# HC32K118 register map
File version: 1.0
CPU: CM0+ r0p1, little endian, no MPU, no FPU, 2 interrupt priority bits
Registers are 32-bit, read-write, reset 0x0 unless marked. A register's access mark holds for its fields unless they carry their own. Offsets are from the block's base; [hi:lo] are bit positions; {n}, {i} and the like mark numbered series; 'fields as' and 'values as' point back to an identical list.

## ICGA
Base 0x01000A00
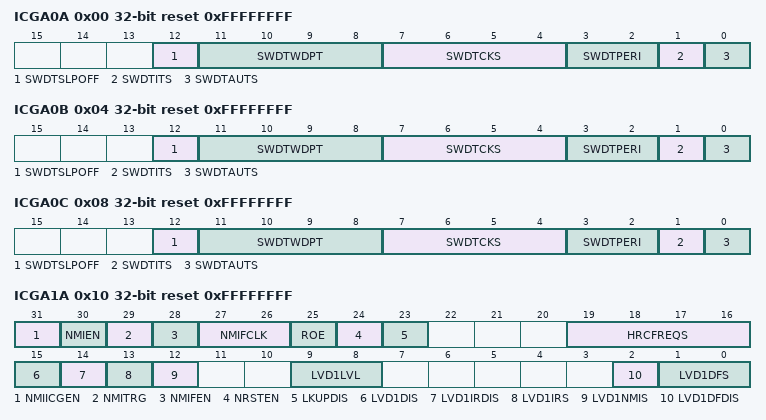
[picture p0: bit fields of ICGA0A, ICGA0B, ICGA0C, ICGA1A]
0x00 ICGA0A ro reset 0xFFFFFFFF
  [12] SWDTSLPOFF, [11:8] SWDTWDPT, [7:4] SWDTCKS, [3:2] SWDTPERI, [1] SWDTITS, [0] SWDTAUTS
0x04 ICGA0B ro reset 0xFFFFFFFF
  fields as ICGA0A
0x08 ICGA0C ro reset 0xFFFFFFFF
  fields as ICGA0A
0x10 ICGA1A ro reset 0xFFFFFFFF
  [31] NMIICGEN, [30] NMIEN, [29] NMITRG, [28] NMIFEN, [27:26] NMIFCLK, [25] ROE, [24] NRSTEN, [23] LKUPDIS, [19:16] HRCFREQS, [15] LVD1DIS, [14] LVD1IRDIS, [13] LVD1IRS, [12] LVD1NMIS, [9:8] LVD1LVL, [2] LVD1DFDIS, [1:0] LVD1DFS
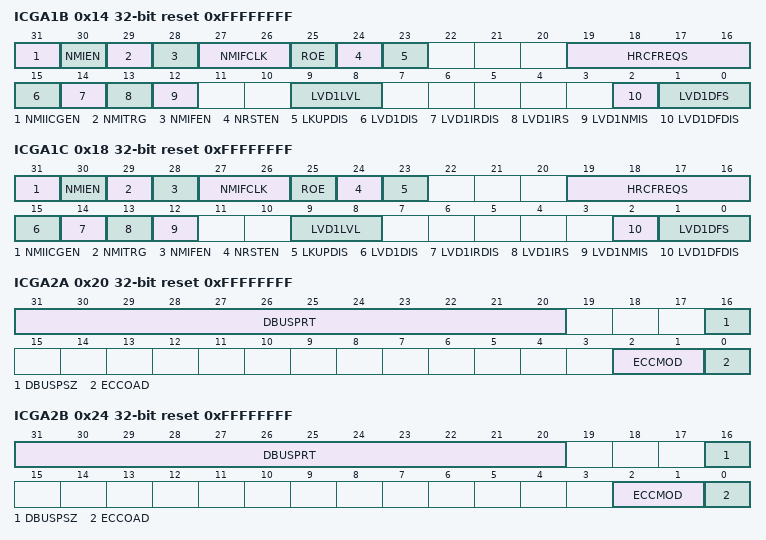
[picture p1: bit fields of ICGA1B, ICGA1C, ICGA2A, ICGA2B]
0x14 ICGA1B ro reset 0xFFFFFFFF
  fields as ICGA1A
0x18 ICGA1C ro reset 0xFFFFFFFF
  fields as ICGA1A
0x20 ICGA2A ro reset 0xFFFFFFFF
  [31:20] DBUSPRT, [16] DBUSPSZ, [2:1] ECCMOD, [0] ECCOAD
0x24 ICGA2B ro reset 0xFFFFFFFF
  [31:20] DBUSPRT, [16] DBUSPSZ, [2:1] ECCMOD, [0] ECCOAD
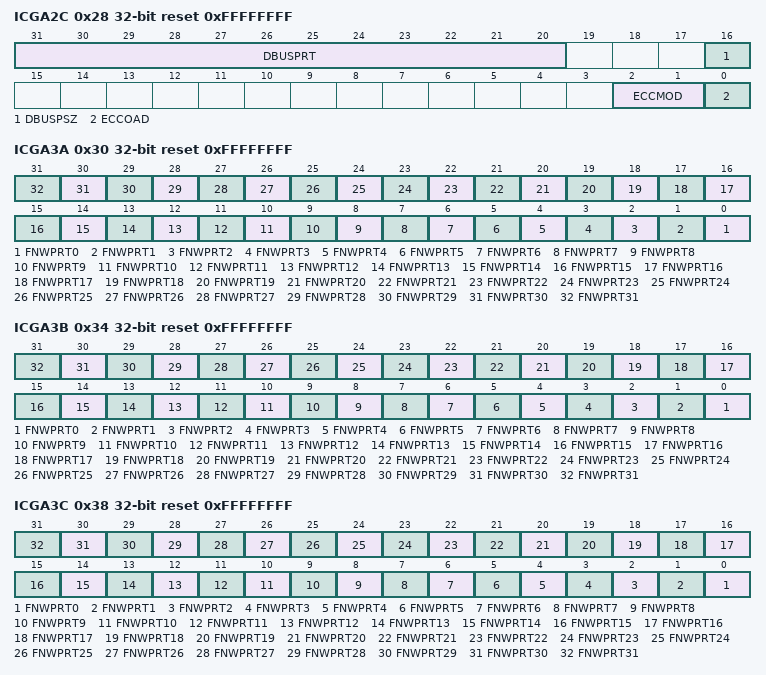
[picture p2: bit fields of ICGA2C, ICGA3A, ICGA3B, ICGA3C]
0x28 ICGA2C ro reset 0xFFFFFFFF
  [31:20] DBUSPRT, [16] DBUSPSZ, [2:1] ECCMOD, [0] ECCOAD
0x30 ICGA3A ro reset 0xFFFFFFFF
  [n] FNWPRT{n} (n=0..31)
0x34 ICGA3B ro reset 0xFFFFFFFF
  [n] FNWPRT{n} (n=0..31)
0x38 ICGA3C ro reset 0xFFFFFFFF
  [n] FNWPRT{n} (n=0..31)
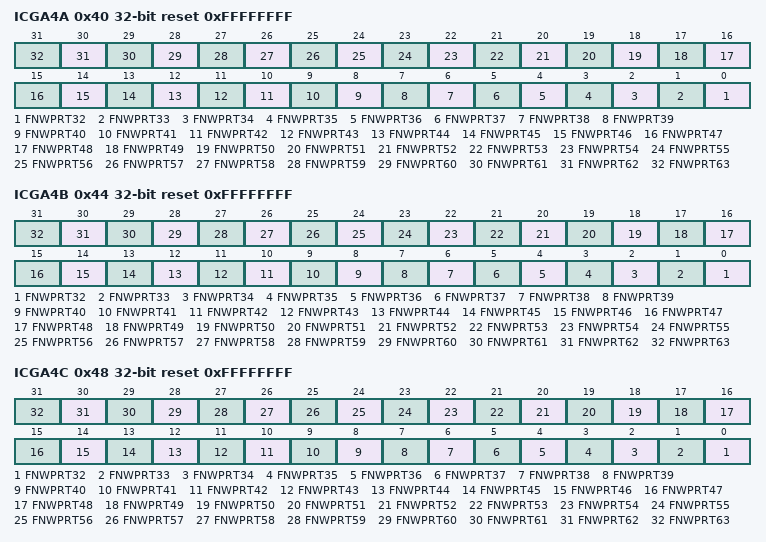
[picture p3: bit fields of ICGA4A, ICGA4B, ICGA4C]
0x40 ICGA4A ro reset 0xFFFFFFFF
  [n-32] FNWPRT{n} (n=32..63)
0x44 ICGA4B ro reset 0xFFFFFFFF
  [n-32] FNWPRT{n} (n=32..63)
0x48 ICGA4C ro reset 0xFFFFFFFF
  [n-32] FNWPRT{n} (n=32..63)

## ICGB
Base 0x40017800
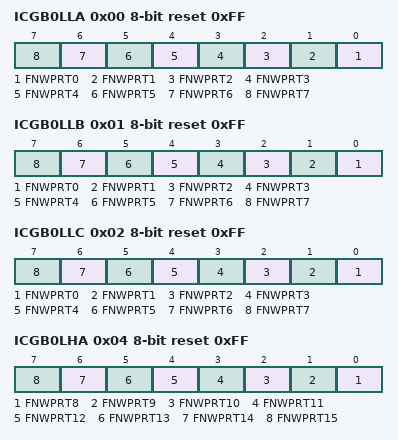
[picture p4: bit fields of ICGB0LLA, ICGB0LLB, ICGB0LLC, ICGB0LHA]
0x00 ICGB0LLA 8-bit ro reset 0xFF
  [n] FNWPRT{n} (n=0..7)
0x01 ICGB0LLB 8-bit ro reset 0xFF
  [n] FNWPRT{n} (n=0..7)
0x02 ICGB0LLC 8-bit ro reset 0xFF
  [n] FNWPRT{n} (n=0..7)
0x04 ICGB0LHA 8-bit ro reset 0xFF
  [n-8] FNWPRT{n} (n=8..15)
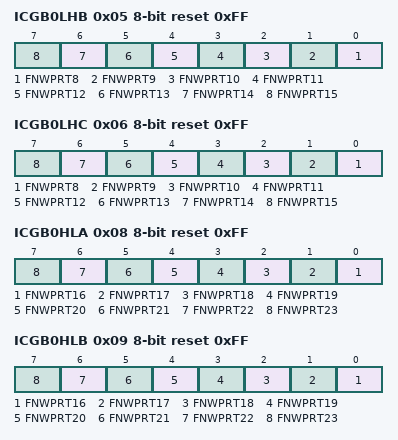
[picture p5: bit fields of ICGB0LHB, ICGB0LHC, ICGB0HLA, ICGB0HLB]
0x05 ICGB0LHB 8-bit ro reset 0xFF
  [n-8] FNWPRT{n} (n=8..15)
0x06 ICGB0LHC 8-bit ro reset 0xFF
  [n-8] FNWPRT{n} (n=8..15)
0x08 ICGB0HLA 8-bit ro reset 0xFF
  [n-16] FNWPRT{n} (n=16..23)
0x09 ICGB0HLB 8-bit ro reset 0xFF
  [n-16] FNWPRT{n} (n=16..23)
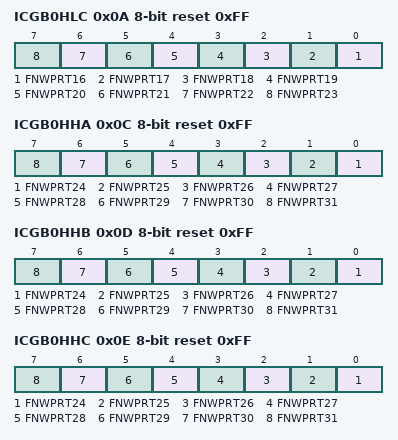
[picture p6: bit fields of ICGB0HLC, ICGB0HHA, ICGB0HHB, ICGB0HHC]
0x0A ICGB0HLC 8-bit ro reset 0xFF
  [n-16] FNWPRT{n} (n=16..23)
0x0C ICGB0HHA 8-bit ro reset 0xFF
  [n-24] FNWPRT{n} (n=24..31)
0x0D ICGB0HHB 8-bit ro reset 0xFF
  [n-24] FNWPRT{n} (n=24..31)
0x0E ICGB0HHC 8-bit ro reset 0xFF
  [n-24] FNWPRT{n} (n=24..31)
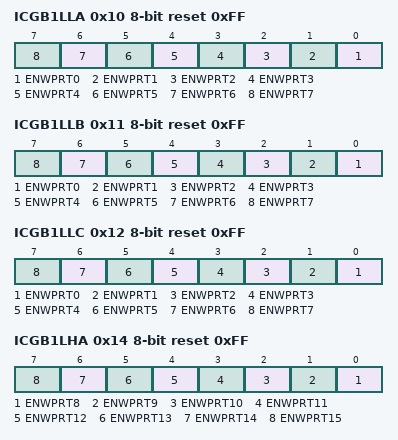
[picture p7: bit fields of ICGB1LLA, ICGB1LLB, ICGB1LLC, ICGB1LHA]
0x10 ICGB1LLA 8-bit ro reset 0xFF
  [n] ENWPRT{n} (n=0..7)
0x11 ICGB1LLB 8-bit ro reset 0xFF
  [n] ENWPRT{n} (n=0..7)
0x12 ICGB1LLC 8-bit ro reset 0xFF
  [n] ENWPRT{n} (n=0..7)
0x14 ICGB1LHA 8-bit ro reset 0xFF
  [n-8] ENWPRT{n} (n=8..15)
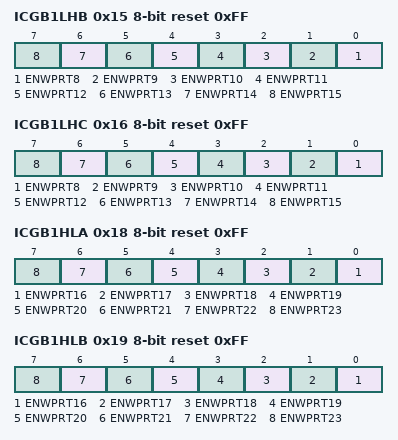
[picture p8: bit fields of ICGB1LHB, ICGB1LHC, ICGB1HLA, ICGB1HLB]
0x15 ICGB1LHB 8-bit ro reset 0xFF
  [n-8] ENWPRT{n} (n=8..15)
0x16 ICGB1LHC 8-bit ro reset 0xFF
  [n-8] ENWPRT{n} (n=8..15)
0x18 ICGB1HLA 8-bit ro reset 0xFF
  [n-16] ENWPRT{n} (n=16..23)
0x19 ICGB1HLB 8-bit ro reset 0xFF
  [n-16] ENWPRT{n} (n=16..23)
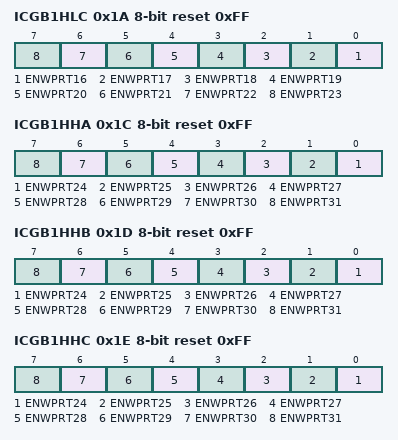
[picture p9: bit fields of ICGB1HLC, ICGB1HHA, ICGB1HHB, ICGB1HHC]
0x1A ICGB1HLC 8-bit ro reset 0xFF
  [n-16] ENWPRT{n} (n=16..23)
0x1C ICGB1HHA 8-bit ro reset 0xFF
  [n-24] ENWPRT{n} (n=24..31)
0x1D ICGB1HHB 8-bit ro reset 0xFF
  [n-24] ENWPRT{n} (n=24..31)
0x1E ICGB1HHC 8-bit ro reset 0xFF
  [n-24] ENWPRT{n} (n=24..31)

## INTC
Base 0x40011000
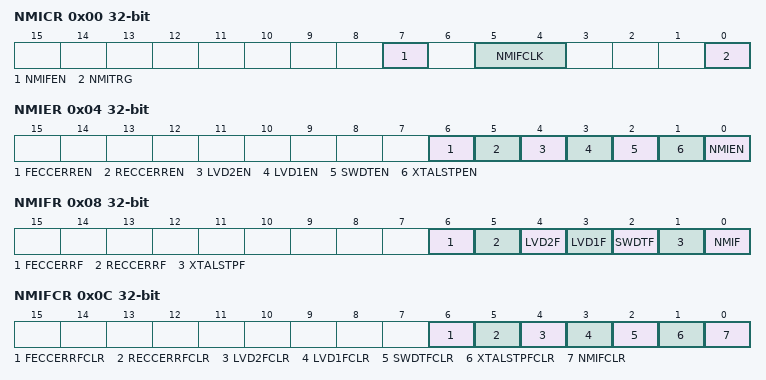
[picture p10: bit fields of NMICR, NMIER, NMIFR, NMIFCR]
0x00 NMICR
  [7] NMIFEN, [5:4] NMIFCLK, [0] NMITRG
0x04 NMIER
  [6] FECCERREN, [5] RECCERREN, [4] LVD2EN, [3] LVD1EN, [2] SWDTEN, [1] XTALSTPEN, [0] NMIEN
0x08 NMIFR ro
  [6] FECCERRF, [5] RECCERRF, [4] LVD2F, [3] LVD1F, [2] SWDTF, [1] XTALSTPF, [0] NMIF
0x0C NMIFCR wo
  [6] FECCERRFCLR, [5] RECCERRFCLR, [4] LVD2FCLR, [3] LVD1FCLR, [2] SWDTFCLR, [1] XTALSTPFCLR, [0] NMIFCLR
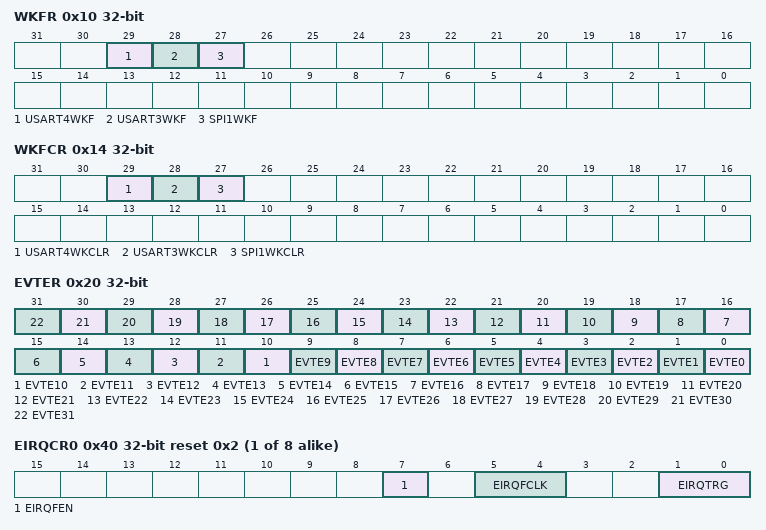
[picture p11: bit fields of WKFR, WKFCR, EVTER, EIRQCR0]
0x10 WKFR ro
  [29] USART4WKF, [28] USART3WKF, [27] SPI1WKF
0x14 WKFCR wo
  [29] USART4WKCLR, [28] USART3WKCLR, [27] SPI1WKCLR
0x20 EVTER
  [n] EVTE{n} (n=0..31)
0x3C FPRCR
  [7:0] FPRC
{0x40+4i} EIRQCR{i} reset 0x2 (i=0..7)
  [7] EIRQFEN, [5:4] EIRQFCLK, [1:0] EIRQTRG
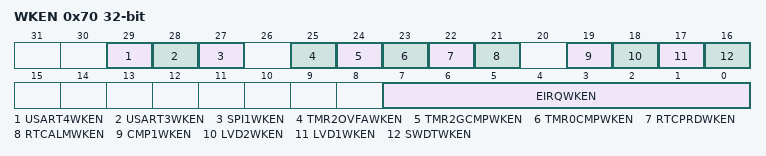
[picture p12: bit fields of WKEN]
0x70 WKEN
  [29] USART4WKEN, [28] USART3WKEN, [27] SPI1WKEN, [25] TMR2OVFAWKEN, [24] TMR2GCMPWKEN, [23] TMR0CMPWKEN, [22] RTCPRDWKEN, [21] RTCALMWKEN, [19] CMP1WKEN, [18] LVD2WKEN, [17] LVD1WKEN, [16] SWDTWKEN, [7:0] EIRQWKEN
0x74 EIFR ro
  [7:0] EIF
0x78 EIFCR wo
  [7:0] EIFCLR
{0x80+4i} INTEN{i} reset 0xFFFFFFFF (i=0..3)
  [31:0] INTEN
